AUTOSAR XML (schema 00051)
standard types defined: boolean, float64, uint16, uint32
package /Components
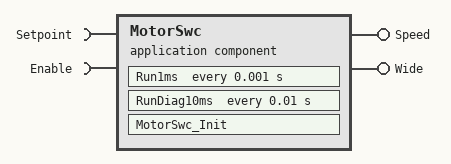
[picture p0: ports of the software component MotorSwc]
  application sw component type MotorSwc
    require port Setpoint: nonqueued-receiver-com-spec{data-element=Setpoint, init-value=0}, required-interface=Setpoint
    require port Enable: nonqueued-receiver-com-spec{data-element=Enable, init-value=0}, required-interface=Enable
    provide port Speed: nonqueued-sender-com-spec{data-element=Speed, init-value=0}, provided-interface=Speed
    provide port Wide: nonqueued-sender-com-spec{data-element=Wide, init-value=0}, provided-interface=Wide
    behavior MotorSwc_IB
      timing event Event_Run1ms: start-on-event=Run1ms, period=0.001
      timing event Event_RunDiag10ms: start-on-event=RunDiag10ms, period=0.01
      runnable MotorSwc_Init
        data-send-points:
          access OUT_Speed_Speed: accessed-variable=Speed.Speed
      runnable Run1ms
        data-receive-point-by-arguments:
          access IN_Setpoint_Setpoint: accessed-variable=Setpoint.Setpoint
          access IN_Enable_Enable: accessed-variable=Enable.Enable
        data-send-points:
          access OUT_Speed_Speed: accessed-variable=Speed.Speed
          access OUT_Wide_Wide: accessed-variable=Wide.Wide
      runnable RunDiag10ms
        data-receive-point-by-arguments:
          access IN_Setpoint_Setpoint: accessed-variable=Setpoint.Setpoint
package /Interfaces
  4 x sender receiver interface:
    Setpoint
      data Setpoint: type=uint16
    Enable
      data Enable: type=boolean
    Speed
      data Speed: type=uint32
    Wide
      data Wide: type=float64
